# STM32H7R7xx register map
File version: 1.0
Registers are 32-bit, read-write, reset 0x0 unless marked. A register's access mark holds for its fields unless they carry their own. Offsets are from the block's base; [hi:lo] are bit positions; 'fields as' and 'values as' point back to an identical list.

## DCMIPP
Base 0x50002000
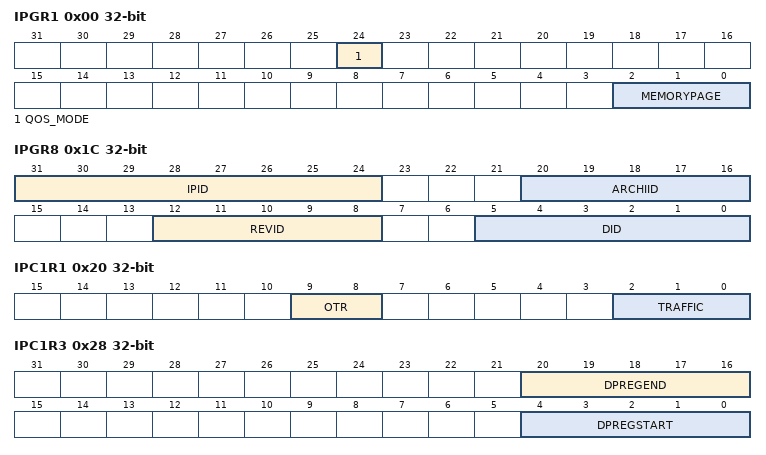
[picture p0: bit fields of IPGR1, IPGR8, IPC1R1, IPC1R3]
0x00 IPGR1 — IP-Plug global register 1
  [24] QOS_MODE — Quality Of Service
  [2:0] MEMORYPAGE — MEMORYPAGE[2:0]
0x04 IPGR2 — IP-Plug global register 2
  [0] PSTART — request to lock the IP-Plug
0x08 IPGR3 — IP-Plug global register 3
  [0] IDLE — request to lock the IP-Plug
0x1C IPGR8 — IP-Plug global register 8
  [31:24] IPID — IPPID[7:0]: IP identifier
  [20:16] ARCHIID — ARCHIID[4:0]: architecture identifier
  [12:8] REVID — REVID[4:0]: revision identifier
  [5:0] DID — DID[5:0]: division identifier
0x20 IPC1R1 — IP-Plug client 1 register 1
  [9:8] OTR — OTR[1:0]: max outstanding transactions
  [2:0] TRAFFIC — TRAFFIC[2:0]
0x24 IPC1R2 — IP-Plug client 1 register 2
  [19:16] WLRU — WLRU[3:0]: ratio for WLRU[3:0] arbitration
0x28 IPC1R3 — IP-Plug client 1 register 3
  [20:16] DPREGEND — DPREGEND[4:0]: end word
  [4:0] DPREGSTART — DPREGSTART[4:0]: start word
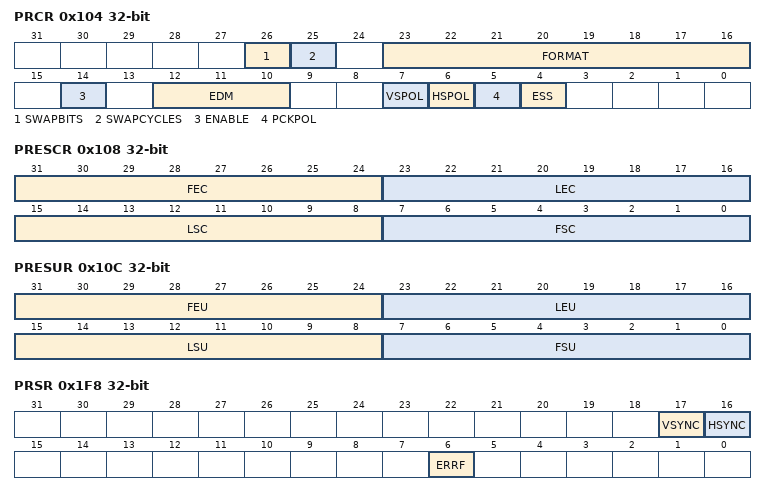
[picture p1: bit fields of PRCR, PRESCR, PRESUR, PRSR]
0x104 PRCR — Parallel interface control register
  [26] SWAPBITS — swap lsb vs msb
  [25] SWAPCYCLES — swap data
  [23:16] FORMAT — FORMAT[7:0]
  [14] ENABLE — Parallel Interface enable
  [12:10] EDM — EDM[2:0]: Extended data mode
  [7] VSPOL — Vertical synchronization polarity
  [6] HSPOL — Horizontal synchronization polarity
  [5] PCKPOL — Pixel clock polarity
  [4] ESS — Embedded synchronization select
0x108 PRESCR — Parallel interface embedded sync code register
  [31:24] FEC — Frame end delimiter code
  [23:16] LEC — Line end delimiter code
  [15:8] LSC — Line start delimiter code
  [7:0] FSC — Frame start delimiter code
0x10C PRESUR — Parallel interface embedded sync unmask register
  [31:24] FEU — Frame end delimiter unmask
  [23:16] LEU — Line end delimiter unmask
  [15:8] LSU — Line start delimiter unmask
  [7:0] FSU — Frame start delimiter unmask
0x1F4 PRIER — Parallel interface interrupt enable register
  [6] ERRIE — Synchronization error interrupt enable
0x1F8 PRSR — Parallel interface status register
  [17] VSYNC
  [16] HSYNC
  [6] ERRF — Synchronization error raw interrupt status
0x1FC PRFCR — Parallel interface interrupt clear register
  [6] CERRF — Synchronization error interrupt status clear
0x204 CMCR — Common configuration register
  [4] CFC — Clear frame counter
0x208 CMFRCR — Common frame counter register
  [31:0] FRMCNT — FRMCNT[31:0]: frame counter
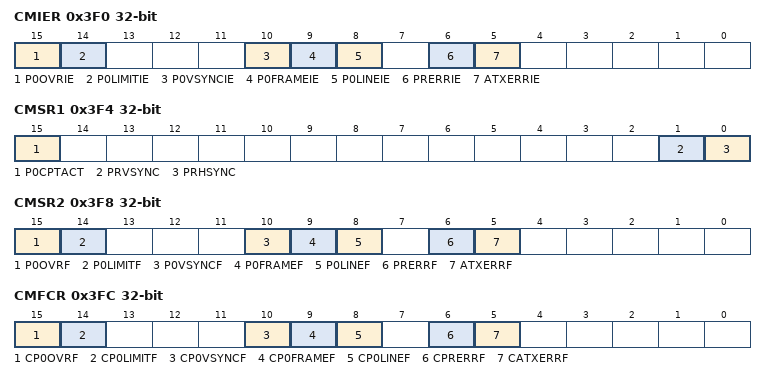
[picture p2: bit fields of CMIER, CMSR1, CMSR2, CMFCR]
0x3F0 CMIER — Common interrupt enable register
  [15] P0OVRIE — Overrun interrupt enable for the Pipe0
  [14] P0LIMITIE — limit interrupt enable for the Pipe0
  [10] P0VSYNCIE — Vertical sync interrupt enable for the Pipe0
  [9] P0FRAMEIE — Frame Capture complete interrupt enable for the Pipe0
  [8] P0LINEIE — multi-Line Capture complete interrupt enable for the Pipe0
  [6] PRERRIE — limit interrupt enable for the Parallel Interface
  [5] ATXERRIE — AXI Transfer error interrupt enable for IP_Plug
0x3F4 CMSR1 — Common status register 1
  [15] P0CPTACT — active frame capture for the Pipe0
  [1] PRVSYNC — state of the VSYNC pin
  [0] PRHSYNC — state of the HSYNC pin
0x3F8 CMSR2 — Common status register 2
  [15] P0OVRF — Overrun raw interrupt status flag for the Pipe0
  [14] P0LIMITF — Limit raw interrupt status flag for the Pipe0
  [10] P0VSYNCF — VSYNC raw interrupt status flag for the Pipe0
  [9] P0FRAMEF — Frame Capture completed raw interrupt status flag for the Pipe0
  [8] P0LINEF — multi-Line Capture completed raw interrupt status flag for the Pipe0
  [6] PRERRF — Synchronization error raw interrupt status flag for the Parallel Interface
  [5] ATXERRF — AXI transfer error interrupt status flag for the IPPLUG
0x3FC CMFCR — Common interrupt clear register
  [15] CP0OVRF — Overrun raw interrupt status clear for the Pipe0
  [14] CP0LIMITF — Limit raw interrupt status clear for the Pipe0
  [10] CP0VSYNCF — VSYNC raw interrupt status clear for the Pipe0
  [9] CP0FRAMEF — Frame Capture completed raw interrupt status clear for the Pipe0
  [8] CP0LINEF — multi-Line Capture completed raw interrupt status clear for the Pipe0
  [6] CPRERRF — Synchronization error raw interrupt status clear for the Parallel Interface
  [5] CATXERRF — AXI transfer error interrupt status clear for the IPPLUG
0x404 P0FSCR — Pipe0 flow selection configuration register
  [31] PIPEN — activation of this Pipe
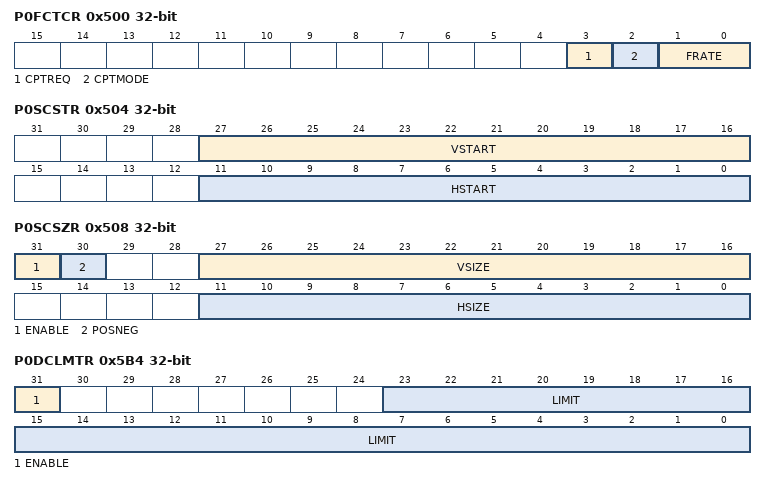
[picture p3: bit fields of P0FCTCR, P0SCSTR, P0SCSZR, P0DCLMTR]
0x500 P0FCTCR — Pipe0 flow control configuration register
  [3] CPTREQ — Capture requested
  [2] CPTMODE — Capture mode
  [1:0] FRATE — FRATE[1:0]: Frame capture rate control
0x504 P0SCSTR — Pipe0 stat/crop start register
  [27:16] VSTART — VSTART[11:0]: vertical start
  [11:0] HSTART — HSTART[11:0]: horizontal start
0x508 P0SCSZR — Pipe0 stat/crop size register
  [31] ENABLE
  [30] POSNEG — Negative area
  [27:16] VSIZE — VSTART[11:0]: vertical size
  [11:0] HSIZE — HSTART[11:0]: horizontal size
0x5B0 P0DCCNTR — Pipe0 dump counter register
  [25:0] CNT — CNT[25:0]: number of data dumped during the frame
0x5B4 P0DCLMTR — Pipe0 dump limit register
  [31] ENABLE
  [23:0] LIMIT — LIMIT[23:0]: maximum number of data dumped during the frame
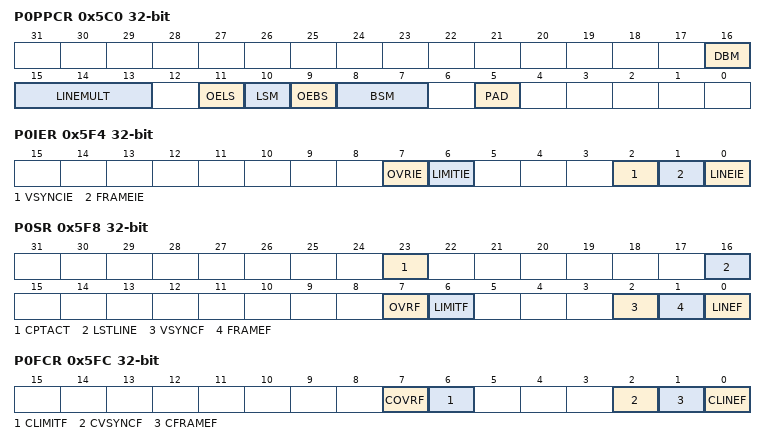
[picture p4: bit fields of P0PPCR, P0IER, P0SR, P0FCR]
0x5C0 P0PPCR — Pipe0 pixel packer configuration register
  [16] DBM — Double buffer mode
  [15:13] LINEMULT — LINEMULT[2:0]
  [11] OELS — Odd/Even Line Select
  [10] LSM — Line Select mode
  [9] OEBS — Odd/Even Byte Select
  [8:7] BSM — Byte Select mode
  [5] PAD — PAD mode
0x5C4 P0PPM0AR1 — Pipe0 pixel packer memory0 address register 1
  [31:0] MOA — Memory 0 address register 1
0x5C8 P0PPM0AR2 — Pipe0 pixel packer memory0 address register 2
  [31:0] MOA — Memory 0 address register 2
0x5F4 P0IER — Pipe0 interrupt enable register
  [7] OVRIE — Overrun interrupt enable
  [6] LIMITIE — Limit interrupt enable
  [2] VSYNCIE — VSYNC interrupt enable
  [1] FRAMEIE — Frame Capture completed interrupt enable
  [0] LINEIE — multi-Line Capture completed interrupt enable
0x5F8 P0SR — Pipe0 status register
  [23] CPTACT — Capture immediate status
  [16] LSTLINE — Last Line Lsb bit
  [7] OVRF — Overrun interrupt status
  [6] LIMITF — Limit interrupt status
  [2] VSYNCF — VSYNC interrupt status
  [1] FRAMEF — Frame Capture completed interrupt status
  [0] LINEF — multi-Line Capture completed interrupt status
0x5FC P0FCR — Pipe0 interrupt clear register
  [7] COVRF — Overrun interrupt status clear
  [6] CLIMITF — Limit interrupt status clear
  [2] CVSYNCF — VSYNC interrupt status clear
  [1] CFRAMEF — Frame Capture completed interrupt status clear
  [0] CLINEF — multi-Line Capture completed interrupt status clear
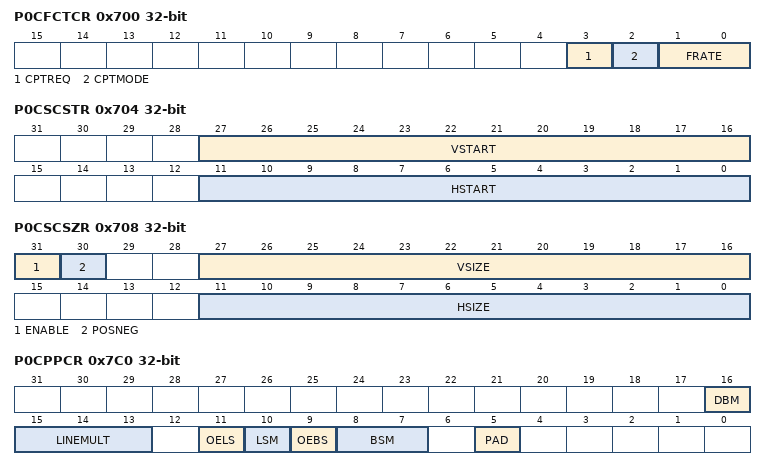
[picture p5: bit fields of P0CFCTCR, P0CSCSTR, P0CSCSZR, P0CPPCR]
0x700 P0CFCTCR — Pipe0 current flow control configuration register
  fields as P0FCTCR
0x704 P0CSCSTR — Pipe0 current stat/crop start register
  fields as P0SCSTR
0x708 P0CSCSZR — Pipe0 current stat/crop size register
  fields as P0SCSZR
0x7C0 P0CPPCR — Pipe0 current pixel packer configuration register
  fields as P0PPCR
0x7C4 P0CPPM0AR1 — Pipe0 current pixel packer memory0 address register 1
  [31:0] MOA — Memory 0 address register 1
0x7C8 P0CPPM0AR2 — Pipe0 current pixel packer memory0 address register 2
  [31:0] MOA — Memory 0 address register 2
